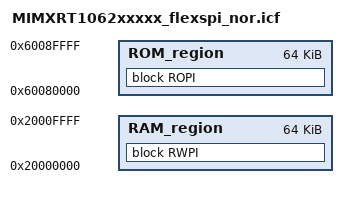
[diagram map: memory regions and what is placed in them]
/*
** ###################################################################
**     Processors:          MIMXRT1062CVJ5A
**                          MIMXRT1062CVL5A
**                          MIMXRT1062DVJ6A
**                          MIMXRT1062DVL6A
**
**     Compiler:            IAR ANSI C/C++ Compiler for ARM
**     Reference manual:    IMXRT1060RM Rev.1, 12/2018 | IMXRT1060SRM Rev.3
**     Version:             rev. 0.1, 2017-01-10
**     Build:               b190730
**
**     Abstract:
**         Linker file for the IAR ANSI C/C++ Compiler for ARM
**
**     Copyright 2016 Freescale Semiconductor, Inc.
**     Copyright 2016-2019 NXP
**     All rights reserved.
**
**     SPDX-License-Identifier: BSD-3-Clause
**
**     http:                 www.nxp.com
**     mail:                 support@nxp.com
**
** ###################################################################
*/

/*###ICF### Section handled by ICF editor, don't touch! ****/
/*-Editor annotation file-*/
/* IcfEditorFile="$TOOLKIT_DIR$\config\ide\IcfEditor\cortex_v1_0.xml" */
/*-Memory Regions-*/
define symbol __ICFEDIT_region_ROM_start__     = 0x60080000;
define symbol __ICFEDIT_region_ROM_end__       = 0x6008FFFF;
define symbol __ICFEDIT_region_RAM_start__     = 0x20000000;
define symbol __ICFEDIT_region_RAM_end__       = 0x2000FFFF;
/*-Sizes-*/
define symbol __ICFEDIT_size_cstack__ = 0x400;
define symbol __ICFEDIT_size_heap__   = 0x200;
/**** End of ICF editor section. ###ICF###*/


define memory mem with size = 4G;
define region ROM_region      = mem:[from __ICFEDIT_region_ROM_start__   to __ICFEDIT_region_ROM_end__];
define region RAM_region      = mem:[from __ICFEDIT_region_RAM_start__   to __ICFEDIT_region_RAM_end__];

define block HEAP      with alignment = 8, size = __ICFEDIT_size_heap__     { };

initialize by copy { readwrite };
do not initialize  { section .noinit };

define movable block ROPI with alignment = 4, fixed order
{
  ro object txm_module_preamble_iar.o,
  ro,
  ro data
};

define movable block RWPI with alignment = 8, fixed order, static base
{
  rw,
  block HEAP
};

place in ROM_region   { block ROPI };
place in RAM_region   { block RWPI };
